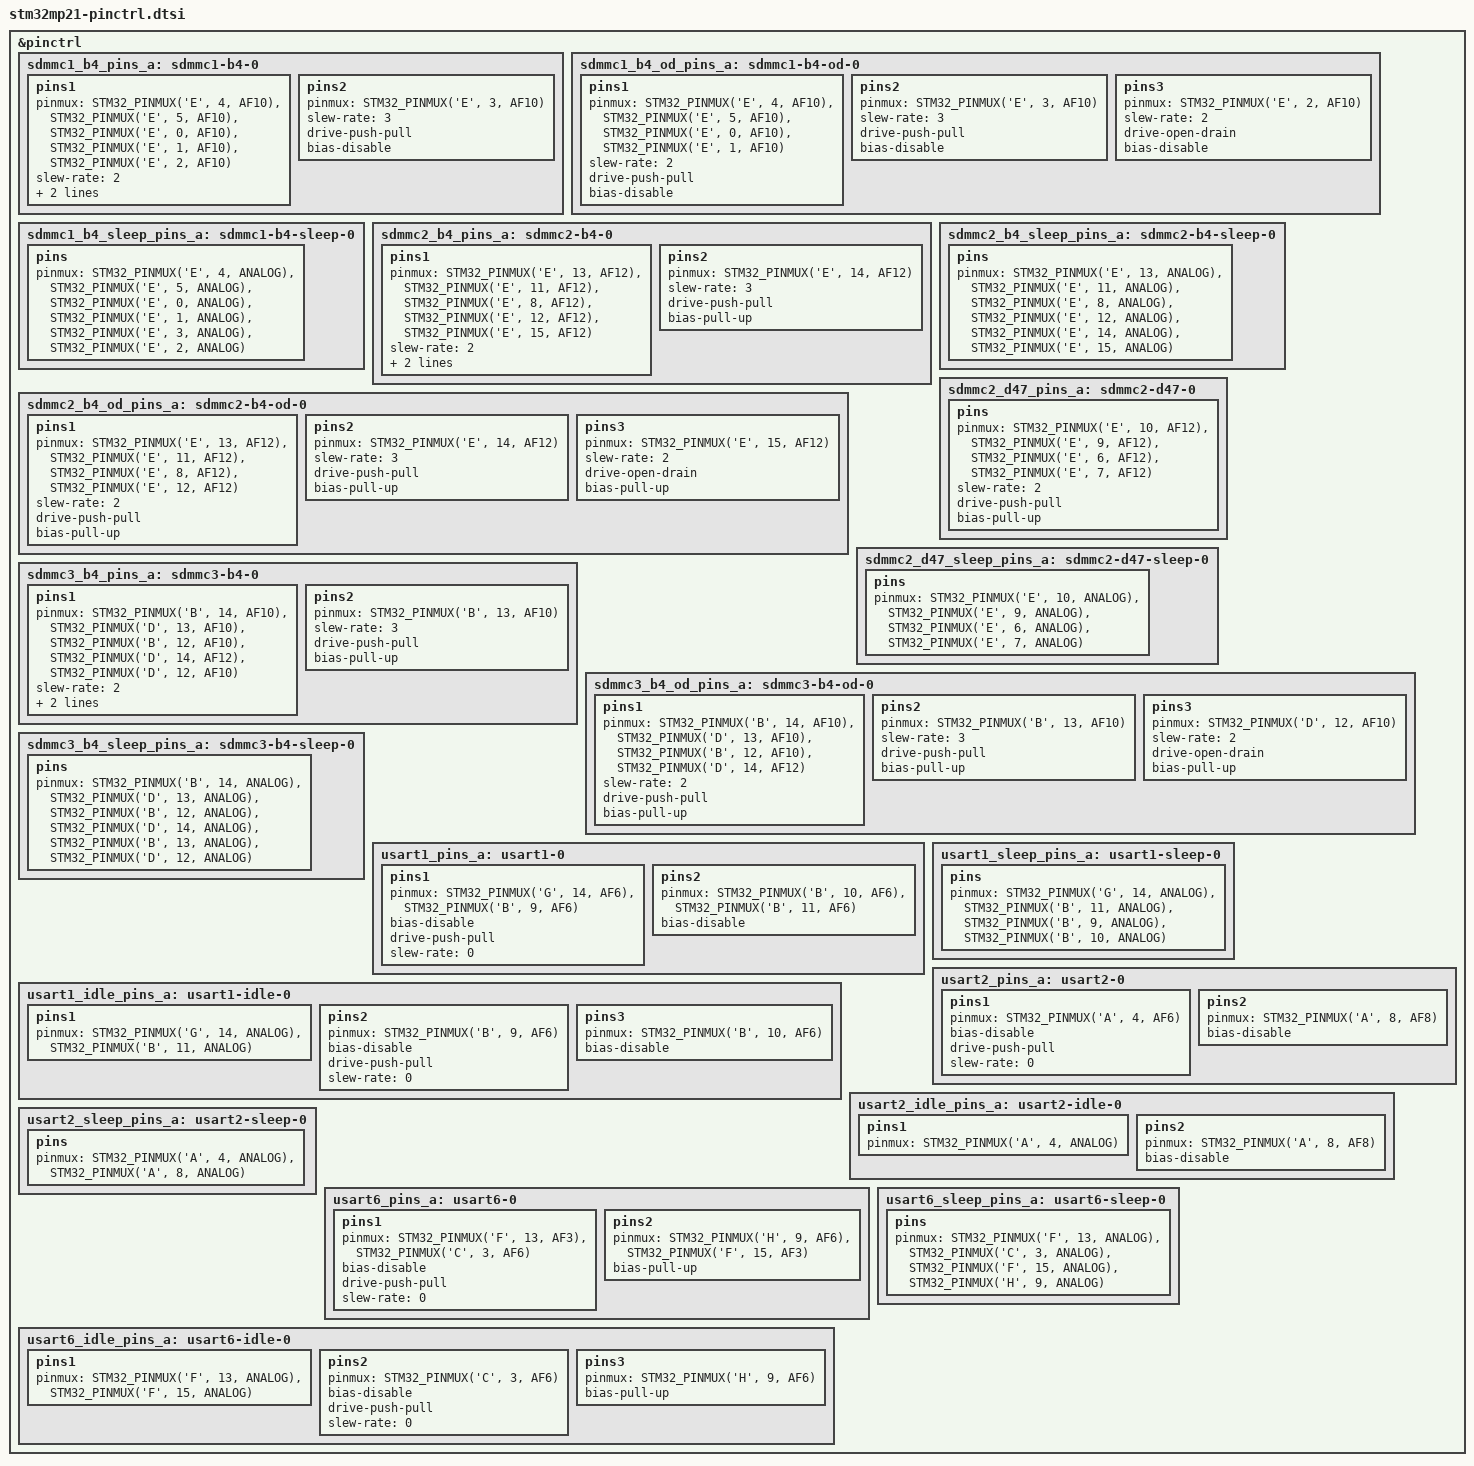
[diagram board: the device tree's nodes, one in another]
// SPDX-License-Identifier: (GPL-2.0-only OR BSD-3-Clause)
/*
 * Copyright (C) 2024, STMicroelectronics - All Rights Reserved
 * Author: Alexandre Torgue <alexandre.torgue@foss.st.com> for STMicroelectronics.
 */
#include <dt-bindings/pinctrl/stm32-pinfunc.h>

&pinctrl {
	sdmmc1_b4_pins_a: sdmmc1-b4-0 {
		pins1 {
			pinmux = <STM32_PINMUX('E', 4, AF10)>, /* SDMMC1_D0 */
				 <STM32_PINMUX('E', 5, AF10)>, /* SDMMC1_D1 */
				 <STM32_PINMUX('E', 0, AF10)>, /* SDMMC1_D2 */
				 <STM32_PINMUX('E', 1, AF10)>, /* SDMMC1_D3 */
				 <STM32_PINMUX('E', 2, AF10)>; /* SDMMC1_CMD */
			slew-rate = <2>;
			drive-push-pull;
			bias-disable;
		};
		pins2 {
			pinmux = <STM32_PINMUX('E', 3, AF10)>; /* SDMMC1_CK */
			slew-rate = <3>;
			drive-push-pull;
			bias-disable;
		};
	};

	sdmmc1_b4_od_pins_a: sdmmc1-b4-od-0 {
		pins1 {
			pinmux = <STM32_PINMUX('E', 4, AF10)>, /* SDMMC1_D0 */
				 <STM32_PINMUX('E', 5, AF10)>, /* SDMMC1_D1 */
				 <STM32_PINMUX('E', 0, AF10)>, /* SDMMC1_D2 */
				 <STM32_PINMUX('E', 1, AF10)>; /* SDMMC1_D3 */
			slew-rate = <2>;
			drive-push-pull;
			bias-disable;
		};
		pins2 {
			pinmux = <STM32_PINMUX('E', 3, AF10)>; /* SDMMC1_CK */
			slew-rate = <3>;
			drive-push-pull;
			bias-disable;
		};
		pins3 {
			pinmux = <STM32_PINMUX('E', 2, AF10)>; /* SDMMC1_CMD */
			slew-rate = <2>;
			drive-open-drain;
			bias-disable;
		};
	};

	sdmmc1_b4_sleep_pins_a: sdmmc1-b4-sleep-0 {
		pins {
			pinmux = <STM32_PINMUX('E', 4, ANALOG)>, /* SDMMC1_D0 */
				 <STM32_PINMUX('E', 5, ANALOG)>, /* SDMMC1_D1 */
				 <STM32_PINMUX('E', 0, ANALOG)>, /* SDMMC1_D2 */
				 <STM32_PINMUX('E', 1, ANALOG)>, /* SDMMC1_D3 */
				 <STM32_PINMUX('E', 3, ANALOG)>, /* SDMMC1_CK */
				 <STM32_PINMUX('E', 2, ANALOG)>; /* SDMMC1_CMD */
		};
	};

	sdmmc2_b4_pins_a: sdmmc2-b4-0 {
		pins1 {
			pinmux = <STM32_PINMUX('E', 13, AF12)>, /* SDMMC2_D0 */
				 <STM32_PINMUX('E', 11, AF12)>, /* SDMMC2_D1 */
				 <STM32_PINMUX('E', 8, AF12)>, /* SDMMC2_D2 */
				 <STM32_PINMUX('E', 12, AF12)>, /* SDMMC2_D3 */
				 <STM32_PINMUX('E', 15, AF12)>; /* SDMMC2_CMD */
			slew-rate = <2>;
			drive-push-pull;
			bias-pull-up;
		};
		pins2 {
			pinmux = <STM32_PINMUX('E', 14, AF12)>; /* SDMMC2_CK */
			slew-rate = <3>;
			drive-push-pull;
			bias-pull-up;
		};
	};

	sdmmc2_b4_od_pins_a: sdmmc2-b4-od-0 {
		pins1 {
			pinmux = <STM32_PINMUX('E', 13, AF12)>, /* SDMMC2_D0 */
				 <STM32_PINMUX('E', 11, AF12)>, /* SDMMC2_D1 */
				 <STM32_PINMUX('E', 8, AF12)>, /* SDMMC2_D2 */
				 <STM32_PINMUX('E', 12, AF12)>; /* SDMMC2_D3 */
			slew-rate = <2>;
			drive-push-pull;
			bias-pull-up;
		};
		pins2 {
			pinmux = <STM32_PINMUX('E', 14, AF12)>; /* SDMMC2_CK */
			slew-rate = <3>;
			drive-push-pull;
			bias-pull-up;
		};
		pins3 {
			pinmux = <STM32_PINMUX('E', 15, AF12)>; /* SDMMC2_CMD */
			slew-rate = <2>;
			drive-open-drain;
			bias-pull-up;
		};
	};

	sdmmc2_b4_sleep_pins_a: sdmmc2-b4-sleep-0 {
		pins {
			pinmux = <STM32_PINMUX('E', 13, ANALOG)>, /* SDMMC2_D0 */
				 <STM32_PINMUX('E', 11, ANALOG)>, /* SDMMC2_D1 */
				 <STM32_PINMUX('E', 8, ANALOG)>, /* SDMMC2_D2 */
				 <STM32_PINMUX('E', 12, ANALOG)>, /* SDMMC2_D3 */
				 <STM32_PINMUX('E', 14, ANALOG)>, /* SDMMC2_CK */
				 <STM32_PINMUX('E', 15, ANALOG)>; /* SDMMC2_CMD */
		};
	};

	sdmmc2_d47_pins_a: sdmmc2-d47-0 {
		pins {
			pinmux = <STM32_PINMUX('E', 10, AF12)>, /* SDMMC2_D4 */
				 <STM32_PINMUX('E', 9, AF12)>, /* SDMMC2_D5 */
				 <STM32_PINMUX('E', 6, AF12)>, /* SDMMC2_D6 */
				 <STM32_PINMUX('E', 7, AF12)>; /* SDMMC2_D7 */
			slew-rate = <2>;
			drive-push-pull;
			bias-pull-up;
		};
	};

	sdmmc2_d47_sleep_pins_a: sdmmc2-d47-sleep-0 {
		pins {
			pinmux = <STM32_PINMUX('E', 10, ANALOG)>, /* SDMMC2_D4 */
				 <STM32_PINMUX('E', 9, ANALOG)>, /* SDMMC2_D5 */
				 <STM32_PINMUX('E', 6, ANALOG)>, /* SDMMC2_D6 */
				 <STM32_PINMUX('E', 7, ANALOG)>; /* SDMMC2_D7 */
		};
	};

	sdmmc3_b4_pins_a: sdmmc3-b4-0 {
		pins1 {
			pinmux = <STM32_PINMUX('B', 14, AF10)>, /* SDMMC3_D0 */
				 <STM32_PINMUX('D', 13, AF10)>, /* SDMMC3_D1 */
				 <STM32_PINMUX('B', 12, AF10)>, /* SDMMC3_D2 */
				 <STM32_PINMUX('D', 14, AF12)>, /* SDMMC3_D3 */
				 <STM32_PINMUX('D', 12, AF10)>; /* SDMMC3_CMD */
			slew-rate = <2>;
			drive-push-pull;
			bias-pull-up;
		};
		pins2 {
			pinmux = <STM32_PINMUX('B', 13, AF10)>; /* SDMMC3_CK */
			slew-rate = <3>;
			drive-push-pull;
			bias-pull-up;
		};
	};

	sdmmc3_b4_od_pins_a: sdmmc3-b4-od-0 {
		pins1 {
			pinmux = <STM32_PINMUX('B', 14, AF10)>, /* SDMMC3_D0 */
				 <STM32_PINMUX('D', 13, AF10)>, /* SDMMC3_D1 */
				 <STM32_PINMUX('B', 12, AF10)>, /* SDMMC3_D2 */
				 <STM32_PINMUX('D', 14, AF12)>; /* SDMMC3_D3 */
			slew-rate = <2>;
			drive-push-pull;
			bias-pull-up;
		};
		pins2 {
			pinmux = <STM32_PINMUX('B', 13, AF10)>; /* SDMMC3_CK */
			slew-rate = <3>;
			drive-push-pull;
			bias-pull-up;
		};
		pins3 {
			pinmux = <STM32_PINMUX('D', 12, AF10)>; /* SDMMC3_CMD */
			slew-rate = <2>;
			drive-open-drain;
			bias-pull-up;
		};
	};

	sdmmc3_b4_sleep_pins_a: sdmmc3-b4-sleep-0 {
		pins {
			pinmux = <STM32_PINMUX('B', 14, ANALOG)>, /* SDMMC1_D0 */
				 <STM32_PINMUX('D', 13, ANALOG)>, /* SDMMC1_D1 */
				 <STM32_PINMUX('B', 12, ANALOG)>, /* SDMMC1_D2 */
				 <STM32_PINMUX('D', 14, ANALOG)>, /* SDMMC1_D3 */
				 <STM32_PINMUX('B', 13, ANALOG)>, /* SDMMC1_CK */
				 <STM32_PINMUX('D', 12, ANALOG)>; /* SDMMC1_CMD */
		};
	};

	usart1_pins_a: usart1-0 {
		pins1 {
			pinmux = <STM32_PINMUX('G', 14, AF6)>, /* USART1_TX */
				 <STM32_PINMUX('B', 9, AF6)>; /* USART1_RTS */
			bias-disable;
			drive-push-pull;
			slew-rate = <0>;
		};
		pins2 {
			pinmux = <STM32_PINMUX('B', 10, AF6)>, /* USART1_RX */
				 <STM32_PINMUX('B', 11, AF6)>; /* USART1_CTS_NSS */
			bias-disable;
		};
	};

	usart1_idle_pins_a: usart1-idle-0 {
		pins1 {
			pinmux = <STM32_PINMUX('G', 14, ANALOG)>, /* USART1_TX */
				 <STM32_PINMUX('B', 11, ANALOG)>; /* USART1_CTS_NSS */
		};
		pins2 {
			pinmux = <STM32_PINMUX('B', 9, AF6)>; /* USART1_RTS */
			bias-disable;
			drive-push-pull;
			slew-rate = <0>;
		};
		pins3 {
			pinmux = <STM32_PINMUX('B', 10, AF6)>; /* USART1_RX */
			bias-disable;
		};
	};

	usart1_sleep_pins_a: usart1-sleep-0 {
		pins {
			pinmux = <STM32_PINMUX('G', 14, ANALOG)>, /* USART1_TX */
				 <STM32_PINMUX('B', 11, ANALOG)>, /* USART1_RTS */
				 <STM32_PINMUX('B', 9, ANALOG)>, /* USART1_CTS_NSS */
				 <STM32_PINMUX('B', 10, ANALOG)>; /* USART1_RX */
		};
	};

	usart2_pins_a: usart2-0 {
		pins1 {
			pinmux = <STM32_PINMUX('A', 4, AF6)>; /* USART2_TX */
			bias-disable;
			drive-push-pull;
			slew-rate = <0>;
		};
		pins2 {
			pinmux = <STM32_PINMUX('A', 8, AF8)>; /* USART2_RX */
			bias-disable;
		};
	};

	usart2_idle_pins_a: usart2-idle-0 {
		pins1 {
			pinmux = <STM32_PINMUX('A', 4, ANALOG)>; /* USART2_TX */
		};
		pins2 {
			pinmux = <STM32_PINMUX('A', 8, AF8)>; /* USART2_RX */
			bias-disable;
		};
	};

	usart2_sleep_pins_a: usart2-sleep-0 {
		pins {
			pinmux = <STM32_PINMUX('A', 4, ANALOG)>, /* USART2_TX */
				 <STM32_PINMUX('A', 8, ANALOG)>; /* USART2_RX */
		};
	};

	usart6_pins_a: usart6-0 {
		pins1 {
			pinmux = <STM32_PINMUX('F', 13, AF3)>, /* USART6_TX */
				 <STM32_PINMUX('C', 3, AF6)>;  /* USART6_RTS */
			bias-disable;
			drive-push-pull;
			slew-rate = <0>;
		};
		pins2 {
			pinmux = <STM32_PINMUX('H', 9, AF6)>, /* USART6_RX */
				 <STM32_PINMUX('F', 15, AF3)>; /* USART6_CTS_NSS */
			bias-pull-up;
		};
	};

	usart6_idle_pins_a: usart6-idle-0 {
		pins1 {
			pinmux = <STM32_PINMUX('F', 13, ANALOG)>, /* USART6_TX */
				 <STM32_PINMUX('F', 15, ANALOG)>; /* USART6_CTS_NSS */
		};
		pins2 {
			pinmux = <STM32_PINMUX('C', 3, AF6)>; /* USART6_RTS */
			bias-disable;
			drive-push-pull;
			slew-rate = <0>;
		};
		pins3 {
			pinmux = <STM32_PINMUX('H', 9, AF6)>; /* USART6_RX */
			bias-pull-up;
		};
	};

	usart6_sleep_pins_a: usart6-sleep-0 {
		pins {
			pinmux = <STM32_PINMUX('F', 13, ANALOG)>, /* USART6_TX */
				 <STM32_PINMUX('C', 3, ANALOG)>,  /* USART6_RTS */
				 <STM32_PINMUX('F', 15, ANALOG)>, /* USART6_CTS_NSS */
				 <STM32_PINMUX('H', 9, ANALOG)>; /* USART6_RX */
		};
	};
};
